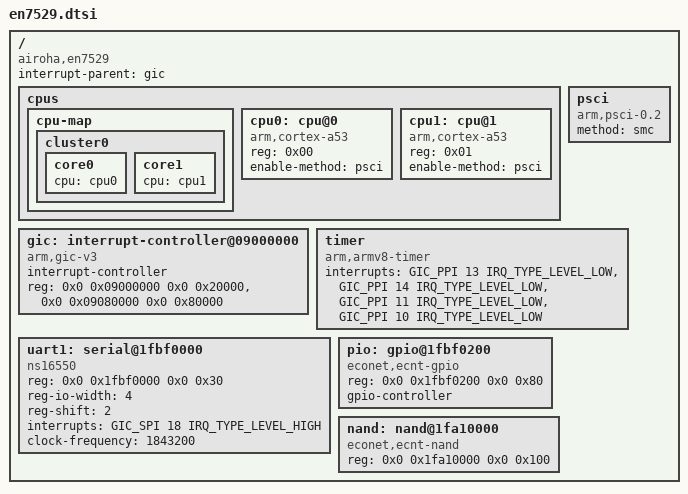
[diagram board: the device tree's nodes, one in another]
// SPDX-License-Identifier: (GPL-2.0-only OR BSD-2-Clause)
/dts-v1/;

#include <dt-bindings/interrupt-controller/irq.h>
#include <dt-bindings/interrupt-controller/arm-gic.h>
#include <dt-bindings/gpio/gpio.h>

/ {
	compatible = "airoha,en7529";
	interrupt-parent = <&gic>;
	#address-cells = <2>;
	#size-cells = <2>;

	cpus {
		#address-cells = <1>;
		#size-cells = <0>;
		cpu-map {
			cluster0 {
				core0 { cpu = <&cpu0>; };
				core1 { cpu = <&cpu1>; };
			};
		};

		cpu0: cpu@0 {
			device_type = "cpu";
			compatible = "arm,cortex-a53";
			reg = <0x00>;
			enable-method = "psci";
		};

		cpu1: cpu@1 {
			device_type = "cpu";
			compatible = "arm,cortex-a53";
			reg = <0x01>;
			enable-method = "psci";
		};
	};

	psci {
		compatible = "arm,psci-0.2";
		method = "smc";
	};

	gic: interrupt-controller@09000000 {
		compatible = "arm,gic-v3";
		interrupt-controller;
		#interrupt-cells = <3>;
		#address-cells = <1>;
		#size-cells = <1>;
		reg = <0x0 0x09000000 0x0 0x20000>,
		      <0x0 0x09080000 0x0 0x80000>;
	};

	timer {
		compatible = "arm,armv8-timer";
		interrupts = <GIC_PPI 13 IRQ_TYPE_LEVEL_LOW>,
			     <GIC_PPI 14 IRQ_TYPE_LEVEL_LOW>,
			     <GIC_PPI 11 IRQ_TYPE_LEVEL_LOW>,
			     <GIC_PPI 10 IRQ_TYPE_LEVEL_LOW>;
	};

	uart1: serial@1fbf0000 {
		compatible = "ns16550";
		reg = <0x0 0x1fbf0000 0x0 0x30>;
		reg-io-width = <4>;
		reg-shift = <2>;
		interrupts = <GIC_SPI 18 IRQ_TYPE_LEVEL_HIGH>;
		clock-frequency = <1843200>;
	};

	pio: gpio@1fbf0200 {
		compatible = "econet,ecnt-gpio";
		reg = <0x0 0x1fbf0200 0x0 0x80>;
		gpio-controller;
		#gpio-cells = <2>;
	};

	nand: nand@1fa10000 {
		compatible = "econet,ecnt-nand";
		reg = <0x0 0x1fa10000 0x0 0x100>;
		#address-cells = <1>;
		#size-cells = <1>;
	};
};
